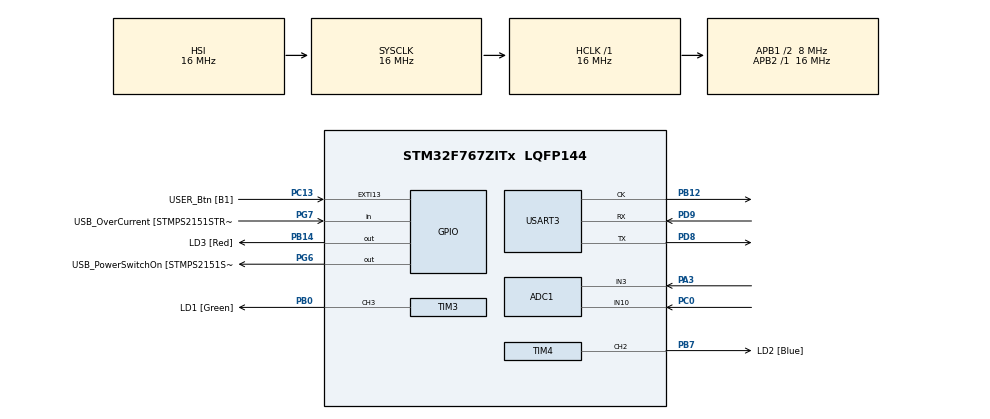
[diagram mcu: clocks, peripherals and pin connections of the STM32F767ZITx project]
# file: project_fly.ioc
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ADC1.Channel-1\#ChannelRegularConversion=ADC_CHANNEL_3
ADC1.Channel-3\#ChannelRegularConversion=ADC_CHANNEL_10
ADC1.ContinuousConvMode=DISABLE
ADC1.DMAContinuousRequests=ENABLE
ADC1.DiscontinuousConvMode=DISABLE
ADC1.NbrOfConversion=2
ADC1.NbrOfConversionFlag=1
ADC1.Rank-1\#ChannelRegularConversion=1
ADC1.Rank-3\#ChannelRegularConversion=2
ADC1.SamplingTime-1\#ChannelRegularConversion=ADC_SAMPLETIME_56CYCLES
ADC1.SamplingTime-3\#ChannelRegularConversion=ADC_SAMPLETIME_56CYCLES
ADC1.ScanConvMode=ADC_SCAN_ENABLE
ADC1.master=1
Dma.ADC1.0.Direction=DMA_PERIPH_TO_MEMORY
Dma.ADC1.0.FIFOMode=DMA_FIFOMODE_DISABLE
Dma.ADC1.0.Instance=DMA2_Stream0
Dma.ADC1.0.MemDataAlignment=DMA_MDATAALIGN_WORD
Dma.ADC1.0.MemInc=DMA_MINC_ENABLE
Dma.ADC1.0.Mode=DMA_NORMAL
Dma.ADC1.0.PeriphDataAlignment=DMA_PDATAALIGN_WORD
Dma.ADC1.0.PeriphInc=DMA_PINC_DISABLE
Dma.ADC1.0.Priority=DMA_PRIORITY_LOW
Dma.Request0=ADC1
FREERTOS.Tasks01=defaultTask,24,256,StartDefaultTask,Default,NULL,Dynamic,NULL,NULL;AdcTask,16,256,AdcRead,As external,NULL,Dynamic,NULL,NULL
FREERTOS.configUSE_NEWLIB_REENTRANT=1
Mcu.Family=STM32F7
Mcu.Name=STM32F767ZITx
Mcu.Package=LQFP144
NVIC.DMA2_Stream0_IRQn=true\:5\:0\:false\:false\:true\:true\:false\:true\:true
NVIC.PriorityGroup=NVIC_PRIORITYGROUP_4
NVIC.TIM8_TRG_COM_TIM14_IRQn=true\:15\:0\:false\:false\:true\:false\:false\:true\:true
NVIC.TimeBase=TIM8_TRG_COM_TIM14_IRQn
NVIC.TimeBaseIP=TIM14
PA10.GPIO_Label=USB_ID
PA10.Signal=USB_OTG_FS_ID
PA11.GPIO_Label=USB_DM
PA11.Signal=USB_OTG_FS_DM
PA12.GPIO_Label=USB_DP
PA12.Signal=USB_OTG_FS_DP
PA13.GPIO_Label=TMS
PA13.Signal=SYS_JTMS-SWDIO
PA14.GPIO_Label=TCK
PA14.Signal=SYS_JTCK-SWCLK
PA3.Signal=ADCx_IN3
PA8.GPIO_Label=USB_SOF [TP1]
PA8.Signal=USB_OTG_FS_SOF
PA9.GPIO_Label=USB_VBUS
PA9.Signal=USB_OTG_FS_VBUS
PB0.GPIO_Label=LD1 [Green]
PB0.Signal=S_TIM3_CH3
PB12.Mode=Synchronous
PB12.Signal=USART3_CK
PB14.GPIO_Label=LD3 [Red]
PB14.Signal=GPIO_Output
PB7.GPIO_Label=LD2 [Blue]
PB7.Signal=S_TIM4_CH2
PC0.Signal=ADCx_IN10
PC13.GPIO_Label=USER_Btn [B1]
PC13.Signal=GPXTI13
PD8.Mode=Synchronous
PD8.Signal=USART3_TX
PD9.Mode=Synchronous
PD9.Signal=USART3_RX
PG6.GPIO_Label=USB_PowerSwitchOn [STMPS2151STR_EN]
PG6.Signal=GPIO_Output
PG7.GPIO_Label=USB_OverCurrent [STMPS2151STR_FAULT]
PG7.Signal=GPIO_Input
ProjectManager.HeapSize=0x200
ProjectManager.StackSize=0x400
ProjectManager.TargetToolchain=STM32CubeIDE
RCC.48MHZClocksFreq_Value=24000000
RCC.AHBFreq_Value=16000000
RCC.APB1CLKDivider=RCC_HCLK_DIV2
RCC.APB1Freq_Value=8000000
RCC.APB1TimFreq_Value=16000000
RCC.APB2Freq_Value=16000000
RCC.APB2TimFreq_Value=16000000
RCC.CortexFreq_Value=16000000
RCC.HCLKFreq_Value=16000000
RCC.HSE_VALUE=16000000
RCC.HSI_VALUE=16000000
RCC.LSE_VALUE=32768
RCC.PLLMUL=RCC_PLL_MUL9
RCC.PRESCALERUSB=RCC_USBCLKSOURCE_PLL_DIV1_5
RCC.SYSCLKFreq_VALUE=16000000
RCC.SYSCLKSourceVirtual=RCC_SYSCLKSOURCE_PLLCLK
RCC.USBFreq_Value=96000000
RCC.VCOOutputFreq_Value=192000000
SH.ADCx_IN10.0=ADC1_IN10,IN10
SH.ADCx_IN3.0=ADC1_IN3,IN3
SH.S_TIM3_CH3.0=TIM3_CH3,PWM Generation3 CH3
SH.S_TIM4_CH2.0=TIM4_CH2,PWM Generation2 CH2
TIM3.Channel-PWM\ Generation3\ CH3=TIM_CHANNEL_3
TIM3.Period=9999
TIM3.Prescaler=0
TIM4.Channel-PWM\ Generation2\ CH2=TIM_CHANNEL_2
TIM4.Period=9999
USART3.VirtualMode-Synchronous=VM_SYNC
VP_FREERTOS_VS_CMSIS_V2.Mode=CMSIS_V2
VP_SYS_VS_tim14.Mode=TIM14
VP_TIM3_VS_ClockSourceINT.Mode=Internal
board=NUCLEO-F767ZI

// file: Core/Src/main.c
/* USER CODE BEGIN Header */
/**
  ******************************************************************************
  * @file           : main.c
  * @brief          : Main program body
  ******************************************************************************
  * @attention
  *
  * Copyright (c) 2025 STMicroelectronics.
  * All rights reserved.
  *
  * This software is licensed under terms that can be found in the LICENSE file
  * in the root directory of this software component.
  * If no LICENSE file comes with this software, it is provided AS-IS.
  *
  ******************************************************************************
  */
/* USER CODE END Header */
#include "main.h"
#include "cmsis_os.h"

/* USER CODE BEGIN Includes */
#include "user.h"
#include <stdio.h>

/* USER CODE END Includes */

ADC_HandleTypeDef hadc1;
DMA_HandleTypeDef hdma_adc1;

TIM_HandleTypeDef htim3;
TIM_HandleTypeDef htim4;

USART_HandleTypeDef husart3;

/* Definitions for defaultTask */
osThreadId_t defaultTaskHandle;
const osThreadAttr_t defaultTask_attributes = {
  .name = "defaultTask",
  .stack_size = 256 * 4,
  .priority = (osPriority_t) osPriorityNormal,
};
/* Definitions for AdcTask */
osThreadId_t AdcTaskHandle;
const osThreadAttr_t AdcTask_attributes = {
  .name = "AdcTask",
  .stack_size = 256 * 4,
  .priority = (osPriority_t) osPriorityBelowNormal,
};

void SystemClock_Config(void);
static void MX_GPIO_Init(void);
static void MX_DMA_Init(void);
static void MX_TIM3_Init(void);
static void MX_TIM4_Init(void);
static void MX_ADC1_Init(void);
static void MX_USART3_Init(void);
void StartDefaultTask(void *argument);
extern void AdcRead(void *argument);

int main(void)
{

  /* MCU Configuration--------------------------------------------------------*/

  /* Reset of all peripherals, Initializes the Flash interface and the Systick. */
  HAL_Init();

  /* Configure the system clock */
  SystemClock_Config();

  /* Initialize all configured peripherals */
  MX_GPIO_Init();
  MX_DMA_Init();
  MX_TIM3_Init();
  MX_TIM4_Init();
  MX_ADC1_Init();
  MX_USART3_Init();
  /* USER CODE BEGIN 2 */
  // blue LED brightness
  setPWM(1000, &htim4, TIM_CHANNEL_2);

  char buf[512];
  // clear COM port terminal
  comprint(buf, sprintf(buf, "\033[1J"));

  /* USER CODE END 2 */

  /* Init scheduler */
  osKernelInitialize();

  /* Create the thread(s) */
  /* creation of defaultTask */
  defaultTaskHandle = osThreadNew(StartDefaultTask, NULL, &defaultTask_attributes);

  /* creation of AdcTask */
  AdcTaskHandle = osThreadNew(AdcRead, NULL, &AdcTask_attributes);

  /* Start scheduler */
  osKernelStart();

  /* We should never get here as control is now taken by the scheduler */

  /* Infinite loop */
  for (;;) {

  }
}

void SystemClock_Config(void)
{
  RCC_OscInitTypeDef RCC_OscInitStruct = {0};
  RCC_ClkInitTypeDef RCC_ClkInitStruct = {0};

  /** Configure the main internal regulator output voltage
  */
  __HAL_RCC_PWR_CLK_ENABLE();
  __HAL_PWR_VOLTAGESCALING_CONFIG(PWR_REGULATOR_VOLTAGE_SCALE3);

  /** Initializes the RCC Oscillators according to the specified parameters
  * in the RCC_OscInitTypeDef structure.
  */
  RCC_OscInitStruct.OscillatorType = RCC_OSCILLATORTYPE_HSI;
  RCC_OscInitStruct.HSIState = RCC_HSI_ON;
  RCC_OscInitStruct.HSICalibrationValue = RCC_HSICALIBRATION_DEFAULT;
  RCC_OscInitStruct.PLL.PLLState = RCC_PLL_NONE;
  if (HAL_RCC_OscConfig(&RCC_OscInitStruct) != HAL_OK)
  {
    Error_Handler();
  }

  /** Initializes the CPU, AHB and APB buses clocks
  */
  RCC_ClkInitStruct.ClockType = RCC_CLOCKTYPE_HCLK|RCC_CLOCKTYPE_SYSCLK
                              |RCC_CLOCKTYPE_PCLK1|RCC_CLOCKTYPE_PCLK2;
  RCC_ClkInitStruct.SYSCLKSource = RCC_SYSCLKSOURCE_HSI;
  RCC_ClkInitStruct.AHBCLKDivider = RCC_SYSCLK_DIV1;
  RCC_ClkInitStruct.APB1CLKDivider = RCC_HCLK_DIV2;
  RCC_ClkInitStruct.APB2CLKDivider = RCC_HCLK_DIV1;

  if (HAL_RCC_ClockConfig(&RCC_ClkInitStruct, FLASH_LATENCY_0) != HAL_OK)
  {
    Error_Handler();
  }
}

static void MX_ADC1_Init(void)
{

  ADC_ChannelConfTypeDef sConfig = {0};

  /** Configure the global features of the ADC (Clock, Resolution, Data Alignment and number of conversion)
  */
  hadc1.Instance = ADC1;
  hadc1.Init.ClockPrescaler = ADC_CLOCK_SYNC_PCLK_DIV2;
  hadc1.Init.Resolution = ADC_RESOLUTION_12B;
  hadc1.Init.ScanConvMode = ADC_SCAN_ENABLE;
  hadc1.Init.ContinuousConvMode = DISABLE;
  hadc1.Init.DiscontinuousConvMode = DISABLE;
  hadc1.Init.ExternalTrigConvEdge = ADC_EXTERNALTRIGCONVEDGE_NONE;
  hadc1.Init.ExternalTrigConv = ADC_SOFTWARE_START;
  hadc1.Init.DataAlign = ADC_DATAALIGN_RIGHT;
  hadc1.Init.NbrOfConversion = 2;
  hadc1.Init.DMAContinuousRequests = ENABLE;
  hadc1.Init.EOCSelection = ADC_EOC_SINGLE_CONV;
  if (HAL_ADC_Init(&hadc1) != HAL_OK)
  {
    Error_Handler();
  }

  /** Configure for the selected ADC regular channel its corresponding rank in the sequencer and its sample time.
  */
  sConfig.Channel = ADC_CHANNEL_3;
  sConfig.Rank = ADC_REGULAR_RANK_1;
  sConfig.SamplingTime = ADC_SAMPLETIME_56CYCLES;
  if (HAL_ADC_ConfigChannel(&hadc1, &sConfig) != HAL_OK)
  {
    Error_Handler();
  }

  /** Configure for the selected ADC regular channel its corresponding rank in the sequencer and its sample time.
  */
  sConfig.Channel = ADC_CHANNEL_10;
  sConfig.Rank = ADC_REGULAR_RANK_2;
  if (HAL_ADC_ConfigChannel(&hadc1, &sConfig) != HAL_OK)
  {
    Error_Handler();
  }

}

static void MX_TIM3_Init(void)
{

  TIM_ClockConfigTypeDef sClockSourceConfig = {0};
  TIM_MasterConfigTypeDef sMasterConfig = {0};
  TIM_OC_InitTypeDef sConfigOC = {0};

  htim3.Instance = TIM3;
  htim3.Init.Prescaler = 0;
  htim3.Init.CounterMode = TIM_COUNTERMODE_UP;
  htim3.Init.Period = 9999;
  htim3.Init.ClockDivision = TIM_CLOCKDIVISION_DIV1;
  htim3.Init.AutoReloadPreload = TIM_AUTORELOAD_PRELOAD_DISABLE;
  if (HAL_TIM_Base_Init(&htim3) != HAL_OK)
  {
    Error_Handler();
  }
  sClockSourceConfig.ClockSource = TIM_CLOCKSOURCE_INTERNAL;
  if (HAL_TIM_ConfigClockSource(&htim3, &sClockSourceConfig) != HAL_OK)
  {
    Error_Handler();
  }
  if (HAL_TIM_PWM_Init(&htim3) != HAL_OK)
  {
    Error_Handler();
  }
  sMasterConfig.MasterOutputTrigger = TIM_TRGO_RESET;
  sMasterConfig.MasterSlaveMode = TIM_MASTERSLAVEMODE_DISABLE;
  if (HAL_TIMEx_MasterConfigSynchronization(&htim3, &sMasterConfig) != HAL_OK)
  {
    Error_Handler();
  }
  sConfigOC.OCMode = TIM_OCMODE_PWM1;
  sConfigOC.Pulse = 0;
  sConfigOC.OCPolarity = TIM_OCPOLARITY_HIGH;
  sConfigOC.OCFastMode = TIM_OCFAST_DISABLE;
  if (HAL_TIM_PWM_ConfigChannel(&htim3, &sConfigOC, TIM_CHANNEL_3) != HAL_OK)
  {
    Error_Handler();
  }
  HAL_TIM_MspPostInit(&htim3);

}

static void MX_TIM4_Init(void)
{

  TIM_MasterConfigTypeDef sMasterConfig = {0};
  TIM_OC_InitTypeDef sConfigOC = {0};

  htim4.Instance = TIM4;
  htim4.Init.Prescaler = 0;
  htim4.Init.CounterMode = TIM_COUNTERMODE_UP;
  htim4.Init.Period = 9999;
  htim4.Init.ClockDivision = TIM_CLOCKDIVISION_DIV1;
  htim4.Init.AutoReloadPreload = TIM_AUTORELOAD_PRELOAD_DISABLE;
  if (HAL_TIM_PWM_Init(&htim4) != HAL_OK)
  {
    Error_Handler();
  }
  sMasterConfig.MasterOutputTrigger = TIM_TRGO_RESET;
  sMasterConfig.MasterSlaveMode = TIM_MASTERSLAVEMODE_DISABLE;
  if (HAL_TIMEx_MasterConfigSynchronization(&htim4, &sMasterConfig) != HAL_OK)
  {
    Error_Handler();
  }
  sConfigOC.OCMode = TIM_OCMODE_PWM1;
  sConfigOC.Pulse = 0;
  sConfigOC.OCPolarity = TIM_OCPOLARITY_HIGH;
  sConfigOC.OCFastMode = TIM_OCFAST_DISABLE;
  if (HAL_TIM_PWM_ConfigChannel(&htim4, &sConfigOC, TIM_CHANNEL_2) != HAL_OK)
  {
    Error_Handler();
  }
  HAL_TIM_MspPostInit(&htim4);

}

static void MX_USART3_Init(void)
{

  husart3.Instance = USART3;
  husart3.Init.BaudRate = 115200;
  husart3.Init.WordLength = USART_WORDLENGTH_8B;
  husart3.Init.StopBits = USART_STOPBITS_1;
  husart3.Init.Parity = USART_PARITY_NONE;
  husart3.Init.Mode = USART_MODE_TX_RX;
  husart3.Init.CLKPolarity = USART_POLARITY_LOW;
  husart3.Init.CLKPhase = USART_PHASE_1EDGE;
  husart3.Init.CLKLastBit = USART_LASTBIT_DISABLE;
  if (HAL_USART_Init(&husart3) != HAL_OK)
  {
    Error_Handler();
  }

}

static void MX_DMA_Init(void)
{

  /* DMA controller clock enable */
  __HAL_RCC_DMA2_CLK_ENABLE();

  /* DMA interrupt init */
  /* DMA2_Stream0_IRQn interrupt configuration */
  HAL_NVIC_SetPriority(DMA2_Stream0_IRQn, 5, 0);
  HAL_NVIC_EnableIRQ(DMA2_Stream0_IRQn);

}

static void MX_GPIO_Init(void)
{
  GPIO_InitTypeDef GPIO_InitStruct = {0};

  /* GPIO Ports Clock Enable */
  __HAL_RCC_GPIOC_CLK_ENABLE();
  __HAL_RCC_GPIOA_CLK_ENABLE();
  __HAL_RCC_GPIOB_CLK_ENABLE();
  __HAL_RCC_GPIOD_CLK_ENABLE();
  __HAL_RCC_GPIOG_CLK_ENABLE();

  /*Configure GPIO pin Output Level */
  HAL_GPIO_WritePin(LD3_GPIO_Port, LD3_Pin, GPIO_PIN_RESET);

  /*Configure GPIO pin Output Level */
  HAL_GPIO_WritePin(USB_PowerSwitchOn_GPIO_Port, USB_PowerSwitchOn_Pin, GPIO_PIN_RESET);

  /*Configure GPIO pin : USER_Btn_Pin */
  GPIO_InitStruct.Pin = USER_Btn_Pin;
  GPIO_InitStruct.Mode = GPIO_MODE_IT_RISING;
  GPIO_InitStruct.Pull = GPIO_NOPULL;
  HAL_GPIO_Init(USER_Btn_GPIO_Port, &GPIO_InitStruct);

  /*Configure GPIO pin : LD3_Pin */
  GPIO_InitStruct.Pin = LD3_Pin;
  GPIO_InitStruct.Mode = GPIO_MODE_OUTPUT_PP;
  GPIO_InitStruct.Pull = GPIO_NOPULL;
  GPIO_InitStruct.Speed = GPIO_SPEED_FREQ_LOW;
  HAL_GPIO_Init(LD3_GPIO_Port, &GPIO_InitStruct);

  /*Configure GPIO pin : USB_PowerSwitchOn_Pin */
  GPIO_InitStruct.Pin = USB_PowerSwitchOn_Pin;
  GPIO_InitStruct.Mode = GPIO_MODE_OUTPUT_PP;
  GPIO_InitStruct.Pull = GPIO_NOPULL;
  GPIO_InitStruct.Speed = GPIO_SPEED_FREQ_LOW;
  HAL_GPIO_Init(USB_PowerSwitchOn_GPIO_Port, &GPIO_InitStruct);

  /*Configure GPIO pin : USB_OverCurrent_Pin */
  GPIO_InitStruct.Pin = USB_OverCurrent_Pin;
  GPIO_InitStruct.Mode = GPIO_MODE_INPUT;
  GPIO_InitStruct.Pull = GPIO_NOPULL;
  HAL_GPIO_Init(USB_OverCurrent_GPIO_Port, &GPIO_InitStruct);

  /*Configure GPIO pins : USB_SOF_Pin USB_ID_Pin USB_DM_Pin USB_DP_Pin */
  GPIO_InitStruct.Pin = USB_SOF_Pin|USB_ID_Pin|USB_DM_Pin|USB_DP_Pin;
  GPIO_InitStruct.Mode = GPIO_MODE_AF_PP;
  GPIO_InitStruct.Pull = GPIO_NOPULL;
  GPIO_InitStruct.Speed = GPIO_SPEED_FREQ_VERY_HIGH;
  GPIO_InitStruct.Alternate = GPIO_AF10_OTG_FS;
  HAL_GPIO_Init(GPIOA, &GPIO_InitStruct);

  /*Configure GPIO pin : USB_VBUS_Pin */
  GPIO_InitStruct.Pin = USB_VBUS_Pin;
  GPIO_InitStruct.Mode = GPIO_MODE_INPUT;
  GPIO_InitStruct.Pull = GPIO_NOPULL;
  HAL_GPIO_Init(USB_VBUS_GPIO_Port, &GPIO_InitStruct);

}

void StartDefaultTask(void *argument)
{
  /* USER CODE BEGIN 5 */
  /* Infinite loop */
  defaultTask();

  /* USER CODE END 5 */
}

void HAL_TIM_PeriodElapsedCallback(TIM_HandleTypeDef *htim)
{
  if (htim->Instance == TIM14)
  {
    HAL_IncTick();
  }
}

void Error_Handler(void)
{
  __disable_irq();
  while (1)
  {
  }
}
